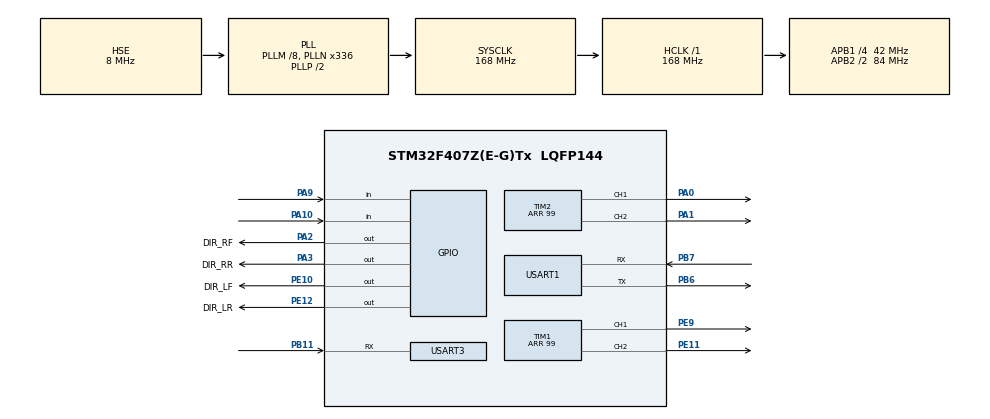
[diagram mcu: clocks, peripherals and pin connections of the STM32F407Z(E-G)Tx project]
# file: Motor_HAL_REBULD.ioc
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Mcu.Family=STM32F4
Mcu.Name=STM32F407Z(E-G)Tx
Mcu.Package=LQFP144
NVIC.PriorityGroup=NVIC_PRIORITYGROUP_2
NVIC.TIM6_DAC_IRQn=true\:3\:0\:true\:false\:true\:false\:true\:true
NVIC.TimeBase=TIM6_DAC_IRQn
NVIC.TimeBaseIP=TIM6
NVIC.USART1_IRQn=true\:3\:3\:true\:false\:true\:true\:true\:true
NVIC.USART3_IRQn=true\:2\:0\:true\:false\:true\:true\:true\:true
PA0-WKUP.Signal=S_TIM2_CH1_ETR
PA1.Signal=S_TIM2_CH2
PA10.Signal=GPIO_Input
PA13.Mode=Serial_Wire
PA13.Signal=SYS_JTMS-SWDIO
PA14.Mode=Serial_Wire
PA14.Signal=SYS_JTCK-SWCLK
PA2.GPIO_Label=DIR_RF
PA2.GPIO_PuPd=GPIO_PULLUP
PA2.GPIO_Speed=GPIO_SPEED_FREQ_HIGH
PA2.Signal=GPIO_Output
PA3.GPIO_Label=DIR_RR
PA3.GPIO_PuPd=GPIO_PULLUP
PA3.GPIO_Speed=GPIO_SPEED_FREQ_HIGH
PA3.Signal=GPIO_Output
PA9.Signal=GPIO_Input
PB6.GPIO_PuPd=GPIO_PULLUP
PB6.Mode=Asynchronous
PB6.Signal=USART1_TX
PB7.GPIO_PuPd=GPIO_PULLUP
PB7.Mode=Asynchronous
PB7.Signal=USART1_RX
PB11.GPIO_PuPd=GPIO_NOPULL
PB11.Mode=Asynchronous
PB11.Signal=USART3_RX
PE10.GPIO_Label=DIR_LF
PE10.GPIO_PuPd=GPIO_PULLUP
PE10.GPIO_Speed=GPIO_SPEED_FREQ_HIGH
PE10.Signal=GPIO_Output
PE11.Signal=S_TIM1_CH2
PE12.GPIO_Label=DIR_LR
PE12.GPIO_PuPd=GPIO_PULLUP
PE12.GPIO_Speed=GPIO_SPEED_FREQ_HIGH
PE12.Signal=GPIO_Output
PE9.Signal=S_TIM1_CH1
PH0-OSC_IN.Mode=HSE-External-Oscillator
PH0-OSC_IN.Signal=RCC_OSC_IN
PH1-OSC_OUT.Mode=HSE-External-Oscillator
PH1-OSC_OUT.Signal=RCC_OSC_OUT
ProjectManager.HeapSize=0x200
ProjectManager.StackSize=0x800
ProjectManager.TargetToolchain=CMake
RCC.48MHZClocksFreq_Value=84000000
RCC.AHBFreq_Value=168000000
RCC.APB1CLKDivider=RCC_HCLK_DIV4
RCC.APB1Freq_Value=42000000
RCC.APB1TimFreq_Value=84000000
RCC.APB2CLKDivider=RCC_HCLK_DIV2
RCC.APB2Freq_Value=84000000
RCC.APB2TimFreq_Value=168000000
RCC.CortexFreq_Value=168000000
RCC.HCLKFreq_Value=168000000
RCC.HSE_VALUE=8000000
RCC.HSI_VALUE=16000000
RCC.LSE_VALUE=32768
RCC.PLLM=8
RCC.PLLN=336
RCC.PLLSourceVirtual=RCC_PLLSOURCE_HSE
RCC.SYSCLKFreq_VALUE=168000000
RCC.SYSCLKSource=RCC_SYSCLKSOURCE_PLLCLK
RCC.VCOOutputFreq_Value=336000000
SH.S_TIM1_CH1.0=TIM1_CH1,PWM Generation1 CH1
SH.S_TIM1_CH2.0=TIM1_CH2,PWM Generation2 CH2
SH.S_TIM2_CH1_ETR.0=TIM2_CH1,PWM Generation1 CH1
SH.S_TIM2_CH2.0=TIM2_CH2,PWM Generation2 CH2
TIM1.AutoReloadPreload=TIM_AUTORELOAD_PRELOAD_ENABLE
TIM1.Channel-PWM\ Generation1\ CH1=TIM_CHANNEL_1
TIM1.Channel-PWM\ Generation2\ CH2=TIM_CHANNEL_2
TIM1.Period=99
TIM1.Pulse-PWM\ Generation1\ CH1=50
TIM1.Pulse-PWM\ Generation2\ CH2=50
TIM2.AutoReloadPreload=TIM_AUTORELOAD_PRELOAD_ENABLE
TIM2.Channel-PWM\ Generation1\ CH1=TIM_CHANNEL_1
TIM2.Channel-PWM\ Generation2\ CH2=TIM_CHANNEL_2
TIM2.Period=99
TIM2.Pulse-PWM\ Generation1\ CH1=50
TIM2.Pulse-PWM\ Generation2\ CH2=50
USART1.VirtualMode=VM_ASYNC
USART3.Mode=MODE_RX
USART3.VirtualMode=VM_ASYNC
VP_SYS_VS_tim6.Mode=TIM6
VP_TIM1_VS_ClockSourceINT.Mode=Internal
VP_TIM2_VS_ClockSourceINT.Mode=Internal
board=custom

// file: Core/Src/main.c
/* USER CODE BEGIN Header */
/**
  ******************************************************************************
  * @file           : main.c
  * @brief          : Main program body
  ******************************************************************************
  * @attention
  *
  * Copyright (c) 2026 STMicroelectronics.
  * All rights reserved.
  *
  * This software is licensed under terms that can be found in the LICENSE file
  * in the root directory of this software component.
  * If no LICENSE file comes with this software, it is provided AS-IS.
  *
  ******************************************************************************
  */
/* USER CODE END Header */
#include "main.h"
#include "tim.h"
#include "usart.h"
#include "gpio.h"

/* USER CODE BEGIN Includes */
#include "app.h"          /* App 层唯一入口: App_Init() / App_Loop() */
/* 注：main() 不再直接调 Motion_*。所有运动都由 App 层的串口命令触发，
 *     需要看接口请翻 App/Inc/motion.h。 */

/* 故障现场输出（X6）：Error_Handler / HardFault 里把现场打出来再停机，
 * 而不是静默 while(1) —— 偶发故障重现不了，现场不打出来就永远查不到。 */
#include "bsp_fault.h"
/* USER CODE END Includes */

void SystemClock_Config(void);

int main(void)
{

  /* MCU Configuration--------------------------------------------------------*/

  /* Reset of all peripherals, Initializes the Flash interface and the Systick. */
  HAL_Init();

  /* Configure the system clock */
  SystemClock_Config();

  /* Initialize all configured peripherals */
  MX_GPIO_Init();
  MX_TIM1_Init();
  MX_TIM2_Init();
  MX_USART1_UART_Init();
  MX_USART3_UART_Init();      /* 遥控接收机 i-BUS：只收，RX=PB11（AF7） */
  /* USER CODE BEGIN 2 */
  App_Init();                 /* 串口接收 + 四电机初始化（全部在 App 层） */

  /* ⚠️ 这里曾经无条件跑六段演示（约 13 秒），已删除。
   *
   * 为什么必须删：
   *   ① 上电就跑四轮 → 一旦 BMS 因为过流切断供电，MCU 掉电复位 →
   *      复位后又跑一遍演示 → 又过流 …… 形成"断电极易反复触发"的正反馈；
   *   ② 这 13 秒里 App_Loop() 一次都不执行，串口命令全部收到但没人处理。
   *
   * 现在上电静止，等上位机命令。需要演示请发 "D"（内容一字未改，
   * 见 App/Src/motion.c 的 Motion_Demo()）。 */
  /* USER CODE END 2 */

  /* Infinite loop */
  while (1)
  {

    /* USER CODE BEGIN 3 */
    App_Loop();               /* 收帧回显 + 流程推进 */
  }
  /* USER CODE END 3 */
}

void SystemClock_Config(void)
{
  RCC_OscInitTypeDef RCC_OscInitStruct = {0};
  RCC_ClkInitTypeDef RCC_ClkInitStruct = {0};

  /** Configure the main internal regulator output voltage
  */
  __HAL_RCC_PWR_CLK_ENABLE();
  __HAL_PWR_VOLTAGESCALING_CONFIG(PWR_REGULATOR_VOLTAGE_SCALE1);

  /** Initializes the RCC Oscillators according to the specified parameters
  * in the RCC_OscInitTypeDef structure.
  */
  RCC_OscInitStruct.OscillatorType = RCC_OSCILLATORTYPE_HSE;
  RCC_OscInitStruct.HSEState = RCC_HSE_ON;
  RCC_OscInitStruct.PLL.PLLState = RCC_PLL_ON;
  RCC_OscInitStruct.PLL.PLLSource = RCC_PLLSOURCE_HSE;
  RCC_OscInitStruct.PLL.PLLM = 8;
  RCC_OscInitStruct.PLL.PLLN = 336;
  RCC_OscInitStruct.PLL.PLLP = RCC_PLLP_DIV2;
  RCC_OscInitStruct.PLL.PLLQ = 4;
  if (HAL_RCC_OscConfig(&RCC_OscInitStruct) != HAL_OK)
  {
    Error_Handler();
  }

  /** Initializes the CPU, AHB and APB buses clocks
  */
  RCC_ClkInitStruct.ClockType = RCC_CLOCKTYPE_HCLK|RCC_CLOCKTYPE_SYSCLK
                              |RCC_CLOCKTYPE_PCLK1|RCC_CLOCKTYPE_PCLK2;
  RCC_ClkInitStruct.SYSCLKSource = RCC_SYSCLKSOURCE_PLLCLK;
  RCC_ClkInitStruct.AHBCLKDivider = RCC_SYSCLK_DIV1;
  RCC_ClkInitStruct.APB1CLKDivider = RCC_HCLK_DIV4;
  RCC_ClkInitStruct.APB2CLKDivider = RCC_HCLK_DIV2;

  if (HAL_RCC_ClockConfig(&RCC_ClkInitStruct, FLASH_LATENCY_5) != HAL_OK)
  {
    Error_Handler();
  }
}

void HAL_TIM_PeriodElapsedCallback(TIM_HandleTypeDef *htim)
{
  if (htim->Instance == TIM6)
  {
    HAL_IncTick();
  }
}

void Error_Handler(void)
{
  /* USER CODE BEGIN Error_Handler_Debug */
  /* X6：先把"是谁失败的"打出来，再停机。
   *
   * 打印的是**返回地址**（调用 Error_Handler 的那一行在哪个函数里），
   * 拿这个地址去查符号就知道是哪个 HAL 初始化失败了：
   *   arm-none-eabi-addr2line -e build/Debug/Motor_HAL_REBULD.elf 0x08001234
   *
   * 注意顺序：先关中断再打印。关中断后串口发送靠轮询 TXE（见 bsp_fault.c），
   * 不依赖 SysTick，所以关中断也能把字发完。 */
  u32 caller = (u32)__builtin_return_address(0);

  __disable_irq();
  Bsp_Fault_DumpError(caller);

  while (1)
  {
  }
  /* USER CODE END Error_Handler_Debug */
}
